# A31L21x register map
Vendor: VENDOR ABOV Semiconductor Co., Ltd.; Series: A31L21x; File version: 1.0
CPU: CM0+ r0p1, little endian, no MPU, no FPU, VTOR, 2 interrupt priority bits
Registers are 32-bit, read-write, reset 0x0 unless marked. A register's access mark holds for its fields unless they carry their own. Offsets are from the block's base; [hi:lo] are bit positions; {n}, {i} and the like mark numbered series; 'fields as' and 'values as' point back to an identical list.

## PMU — Power Management Unit
Base 0x40001900
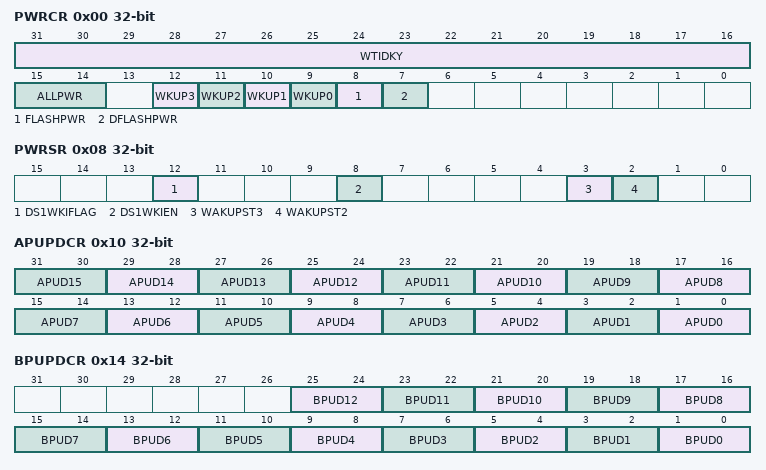
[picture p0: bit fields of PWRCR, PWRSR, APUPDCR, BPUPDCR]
0x00 PWRCR — Power Management Control Register
  [31:16] WTIDKY wo — Write Identification Key (0x5A3C)
    0x5A3C=Value (Key Value (0x5A3C))
  [15:14] ALLPWR — All System and Peripheral Except Always-on Region Power Control
    0=Deep sleep mode 0, can be waked-up by optional and enabled peripherals; 1=Deep sleep mode 1, can be waked-up by optional peripherals and wakeup pins; 2=Deep sleep mode 2, can be waked-up by optional peripherals and wakeup pins; 3=Deep sleep mode 3 (Shutdown), can be waked-up by T60 and wakeup pins
  [12] WKUP3 — Wake-Up function control bit (when the ALLPWR bits are not '00b'), PE6
    0=Disable wake-up function from deep sleep mode; 1=Enable wake-up function from deep sleep mode
  [11] WKUP2 — Wake-Up function control bit (when the ALLPWR bits are not '00b'), PE4
    values as WKUP3
  [10] WKUP1 — Wake-Up function control bit (when the ALLPWR bits are not '00b'), PA2
    values as WKUP3
  [9] WKUP0 — Wake-Up function control bit (when the ALLPWR bits are not '00b'), PA0
    values as WKUP3
  [8] FLASHPWR — Flash Memory Power Control
    0=On (Power On); 1=Off (Power Off)
  [7] DFLASHPWR — Data Flash Memory Power Control
    0=On (Power On); 1=Off (Power Off)
0x08 PWRSR — Power Management Status Register
  [12] DS1WKIFLAG — Deep Sleep Mode 1 Wakeup Interrupt Flag.
    0=No request occurred; 1=Request occurred by wakeup pins. This bit is cleared to '0' when write '1'.
  [8] DS1WKIEN — Deep Sleep Mode 1 Wakeup Interrupt Enable bit by wakeup pins.
    0=Disable deep sleep mode 1 wakeup interrupt; 1=Enable deep sleep mode 1 wakeup interrupt
  [3] WAKUPST3 — Wake-up Reset Status 3 bit. A system reset will occur and this bit is set when the system wakes up from deep sleep mode 3 (PMU_PWRCR.ALLPWR = 3, Shutdown).
    0=NotDetected; 1=Detected (Wake-up reset is detected, This bit is cleared to '0' when write '1'.)
  [2] WAKUPST2 — Wake-up Reset Status 2 bit. A core reset will occur and this bit is set when the system wakes up from deep sleep mode 2 (PMU_PWRCR.ALLPWR = 2).
    values as WAKUPST3
0x10 APUPDCR — Power Port A Pull-up/down Control Register
  [all] fields
    0=DisablePUDR (Disable the pull-up/down resistors.); 1=EnablePUR (Enable the pull-up resistor.); 2=EnablePDR (Enable the pull-down resistor.)
  [2n+1:2n] APUD{n} (n=0..15) — Pull-up/down control bits (when the ALLPWR bits are not '00b')
0x14 BPUPDCR — Power Port B Pull-up/down Control Register
  [all] fields
    0=Disable the pull-up/down resistors; 1=EnablePU (Enable the pull-up resistor.); 2=EnablePD (Enable the pull-down resistor.)
  [2n+1:2n] BPUD{n} (n=0..12) — Pull-up/down control bits (when the ALLPWR bits are not '00b')
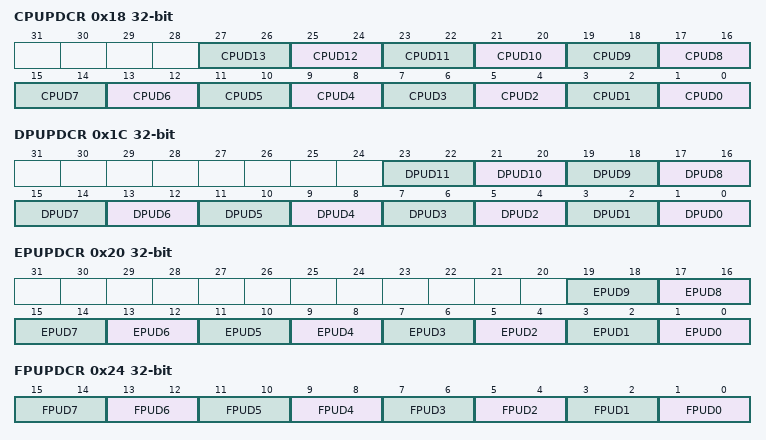
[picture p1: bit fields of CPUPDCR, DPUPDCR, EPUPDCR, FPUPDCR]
0x18 CPUPDCR — Power Port C Pull-up/down Control Register
  [all] fields
    values as the fields of APUPDCR
  [2n+1:2n] CPUD{n} (n=0..13) — Pull-up/down control bits (when the ALLPWR bits are not '00b')
0x1C DPUPDCR — Power Port D Pull-up/down Control Register
  [all] fields
    values as the fields of APUPDCR
  [2n+1:2n] DPUD{n} (n=0..11) — Pull-up/down control bits (when the ALLPWR bits are not '00b')
0x20 EPUPDCR — Power Port E Pull-up/down Control Register
  [all] fields
    values as the fields of APUPDCR
  [2n+1:2n] EPUD{n} (n=0..9) — Pull-up/down control bits (when the ALLPWR bits are not '00b')
0x24 FPUPDCR — Power Port F Pull-up/down Control Register
  [all] fields
    values as the fields of APUPDCR
  [2n+1:2n] FPUD{n} (n=0..7) — Pull-up/down control bits (when the ALLPWR bits are not '00b')
{0x40+i} BKR{i} 8-bit (i=0..31) — Back-up Data Register {i}
  [7:0] BACKUP — Back-up Data
